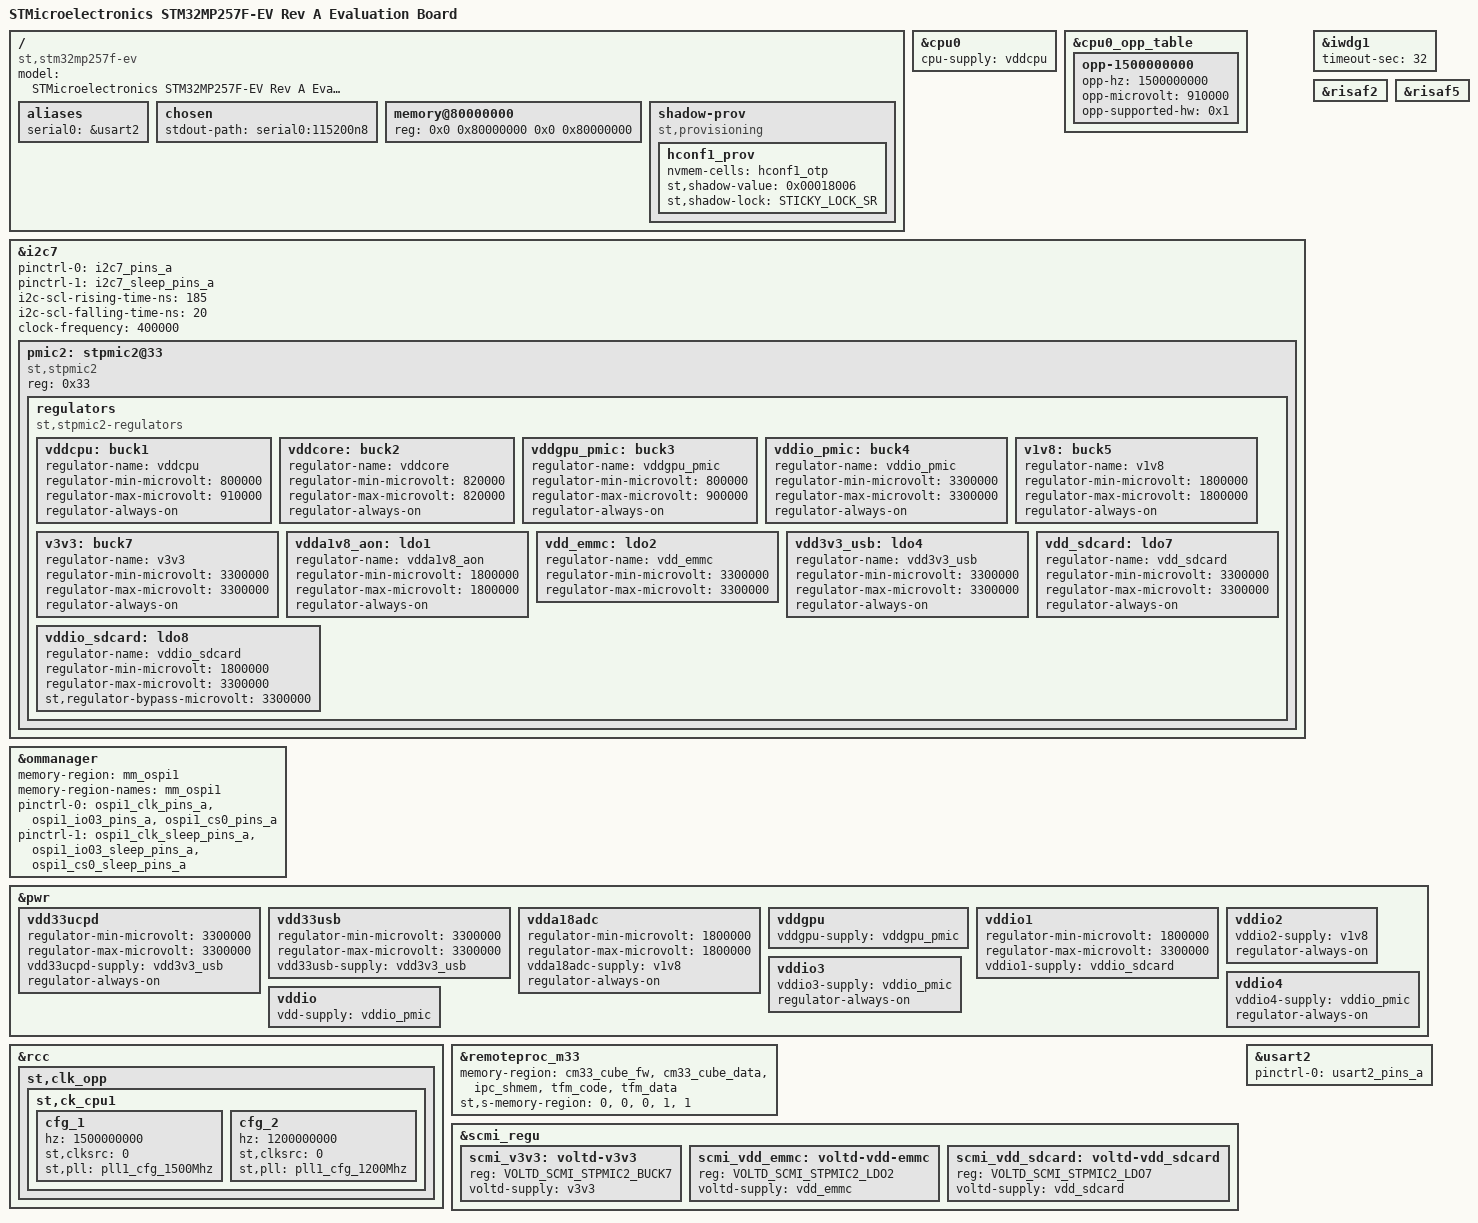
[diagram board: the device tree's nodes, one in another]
// SPDX-License-Identifier: (GPL-2.0+ OR BSD-3-Clause)
/*
 * Copyright (C) STMicroelectronics 2023 - All Rights Reserved
 * Author: Alexandre Torgue <alexandre.torgue@foss.st.com> for STMicroelectronics.
 */

/dts-v1/;

#include <dt-bindings/clock/stm32mp25-clksrc.h>
#include <dt-bindings/regulator/st,stm32mp25-regulator.h>
#include <dt-bindings/reset/stm32mp25-resets.h>
#include <dt-bindings/soc/stm32mp-provisioning.h>
#include <dt-bindings/soc/stm32mp25-rif.h>
#include <dt-bindings/soc/stm32mp25-risab.h>
#include <dt-bindings/soc/stm32mp25-risaf.h>
#include <dt-bindings/soc/stm32mp25-rifsc.h>
#include "stm32mp25x-revA.dtsi"
#include "stm32mp25xf.dtsi"
#include "stm32mp257f-ev-ca35tdcid-rcc.dtsi"
#include "stm32mp257f-ev-ca35tdcid-resmem.dtsi"
#include "stm32mp257f-ev-ca35tdcid-rif.dtsi"
#include "stm32mp25-pinctrl.dtsi"
#include "stm32mp25xxai-pinctrl.dtsi"

/ {
	model = "STMicroelectronics STM32MP257F-EV Rev A Evaluation Board";
	compatible = "st,stm32mp257f-ev", "st,stm32mp257";

	aliases {
		serial0 = &usart2;
	};

	chosen {
		stdout-path = "serial0:115200n8";
	};

	memory@80000000 {
		device_type = "memory";
		reg = <0x0 0x80000000 0x0 0x80000000>;
	};

	shadow-prov {
		compatible = "st,provisioning";
		hconf1_prov {
			nvmem-cells = <&hconf1_otp>;
			st,shadow-value = <0x00018006>;
			st,shadow-lock = <STICKY_LOCK_SR>;
		};
	};
};

&cpu0 {
	cpu-supply = <&vddcpu>;
};

&cpu0_opp_table {
	opp-1500000000 {
		opp-hz = /bits/ 64 <1500000000>;
		opp-microvolt = <910000>;
		opp-supported-hw = <0x1>;
	};
};

&i2c7 {
	pinctrl-names = "default", "sleep";
	pinctrl-0 = <&i2c7_pins_a>;
	pinctrl-1 = <&i2c7_sleep_pins_a>;
	i2c-scl-rising-time-ns = <185>;
	i2c-scl-falling-time-ns = <20>;
	clock-frequency = <400000>;
	status = "okay";
	#address-cells = <1>;
	#size-cells = <0>;

	pmic2: stpmic2@33 {
		compatible = "st,stpmic2";
		reg = <0x33>;
		status = "okay";

		regulators {
			compatible = "st,stpmic2-regulators";

			vddcpu: buck1 {
				regulator-name = "vddcpu";
				regulator-min-microvolt = <800000>;
				regulator-max-microvolt = <910000>;
				regulator-always-on;
			};
			vddcore: buck2 {
				regulator-name = "vddcore";
				regulator-min-microvolt = <820000>;
				regulator-max-microvolt = <820000>;
				regulator-always-on;
			};
			vddgpu_pmic: buck3 {
				regulator-name = "vddgpu_pmic";
				regulator-min-microvolt = <800000>;
				regulator-max-microvolt = <900000>;
				regulator-always-on;
			};
			vddio_pmic: buck4 {
				regulator-name = "vddio_pmic";
				regulator-min-microvolt = <3300000>;
				regulator-max-microvolt = <3300000>;
				regulator-always-on;
			};
			v1v8: buck5 {
				regulator-name = "v1v8";
				regulator-min-microvolt = <1800000>;
				regulator-max-microvolt = <1800000>;
				regulator-always-on;
			};
			v3v3: buck7 {
				regulator-name = "v3v3";
				regulator-min-microvolt = <3300000>;
				regulator-max-microvolt = <3300000>;
				regulator-always-on;
			};
			vdda1v8_aon: ldo1 {
				regulator-name = "vdda1v8_aon";
				regulator-min-microvolt = <1800000>;
				regulator-max-microvolt = <1800000>;
				regulator-always-on;
			};
			vdd_emmc: ldo2 {
				regulator-name = "vdd_emmc";
				regulator-min-microvolt = <3300000>;
				regulator-max-microvolt = <3300000>;
			};
			vdd3v3_usb: ldo4 {
				regulator-name = "vdd3v3_usb";
				regulator-min-microvolt = <3300000>;
				regulator-max-microvolt = <3300000>;
				regulator-always-on;
			};
			vdd_sdcard: ldo7 {
				regulator-name = "vdd_sdcard";
				regulator-min-microvolt = <3300000>;
				regulator-max-microvolt = <3300000>;
				regulator-always-on;
			};
			vddio_sdcard: ldo8 {
				regulator-name = "vddio_sdcard";
				regulator-min-microvolt = <1800000>;
				regulator-max-microvolt = <3300000>;
				st,regulator-bypass-microvolt = <3300000>;
			};
		};
	};
};

&iwdg1 {
	timeout-sec = <32>;
	status = "okay";
};

&ommanager {
	memory-region = <&mm_ospi1>;
	memory-region-names = "mm_ospi1";
	pinctrl-names = "default", "sleep";
	pinctrl-0 = <&ospi1_clk_pins_a
		     &ospi1_io03_pins_a
		     &ospi1_cs0_pins_a>;
	pinctrl-1 = <&ospi1_clk_sleep_pins_a
		     &ospi1_io03_sleep_pins_a
		     &ospi1_cs0_sleep_pins_a>;
	status = "okay";
};

&risaf2 {
	status = "okay";
};

&risaf5 {
	status = "okay";
};

&pwr {
	status = "okay";

	vdd33ucpd: vdd33ucpd {
		status = "okay";
		regulator-min-microvolt = <3300000>;
		regulator-max-microvolt = <3300000>;
		vdd33ucpd-supply = <&vdd3v3_usb>;
		regulator-always-on;
	};

	vdd33usb: vdd33usb {
		status = "okay";
		regulator-min-microvolt = <3300000>;
		regulator-max-microvolt = <3300000>;
		vdd33usb-supply = <&vdd3v3_usb>;
	};

	vdda18adc: vdda18adc {
		status = "okay";
		regulator-min-microvolt = <1800000>;
		regulator-max-microvolt = <1800000>;
		vdda18adc-supply = <&v1v8>;
		regulator-always-on;
	};

	vddgpu: vddgpu {
		status = "okay";
		vddgpu-supply = <&vddgpu_pmic>;
	};

	vddio1: vddio1 {
		status = "okay";
		regulator-min-microvolt = <1800000>;
		regulator-max-microvolt = <3300000>;
		vddio1-supply = <&vddio_sdcard>;
	};

	vddio2: vddio2 {
		status = "okay";
		vddio2-supply = <&v1v8>;
		regulator-always-on;
	};

	vddio3: vddio3 {
		status = "okay";
		vddio3-supply = <&vddio_pmic>;
		regulator-always-on;
	};

	vddio4: vddio4 {
		status = "okay";
		vddio4-supply = <&vddio_pmic>;
		regulator-always-on;
	};

	vddio: vddio {
		status = "okay";
		vdd-supply = <&vddio_pmic>;
	};
};

&rcc {
	st,clk_opp {
		st,ck_cpu1 {
			cfg_1 {
				hz = <1500000000>;
				st,clksrc = <0>;
				st,pll = <&pll1_cfg_1500Mhz>;
			};

			cfg_2 {
				hz = <1200000000>;
				st,clksrc = <0>;
				st,pll = <&pll1_cfg_1200Mhz>;
			};
		};
	};
};

&remoteproc_m33 {
	memory-region = <&cm33_cube_fw>, <&cm33_cube_data>,
			<&ipc_shmem>, <&tfm_code>, <&tfm_data>;
	st,s-memory-region = <0>, <0>, <0>, <1>, <1>;
	status = "okay";
};

&scmi_regu {
	scmi_v3v3: voltd-v3v3 {
		reg = <VOLTD_SCMI_STPMIC2_BUCK7>;
		voltd-supply = <&v3v3>;
	};
	scmi_vdd_emmc: voltd-vdd-emmc {
		reg = <VOLTD_SCMI_STPMIC2_LDO2>;
		voltd-supply = <&vdd_emmc>;
	};
	scmi_vdd_sdcard: voltd-vdd_sdcard {
		reg = <VOLTD_SCMI_STPMIC2_LDO7>;
		voltd-supply = <&vdd_sdcard>;
	};
};

&usart2 {
	pinctrl-names = "default";
	pinctrl-0 = <&usart2_pins_a>;
	status = "okay";
};
